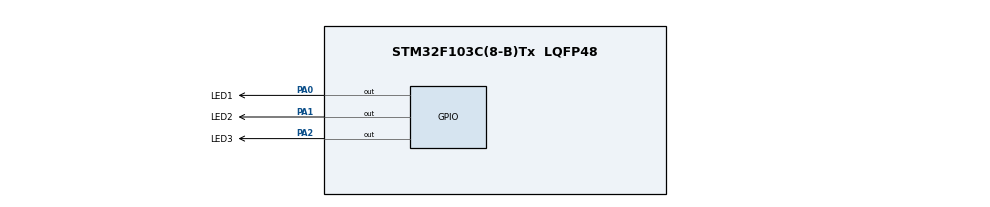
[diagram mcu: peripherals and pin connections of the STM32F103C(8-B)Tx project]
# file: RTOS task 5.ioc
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FREERTOS.Tasks01=defaultTask,0,128,StartDefaultTask,Default,NULL,Dynamic,NULL,NULL;GreenLEDTask,-3,128,green_led,Default,NULL,Dynamic,NULL,NULL;RedLEDTask,0,128,red_led,Default,NULL,Dynamic,NULL,NULL
Mcu.Family=STM32F1
Mcu.Name=STM32F103C(8-B)Tx
Mcu.Package=LQFP48
NVIC.PriorityGroup=NVIC_PRIORITYGROUP_4
PA0-WKUP.GPIO_Label=LED1
PA0-WKUP.Signal=GPIO_Output
PA1.GPIO_Label=LED2
PA1.Signal=GPIO_Output
PA13.Mode=Serial_Wire
PA13.Signal=SYS_JTMS-SWDIO
PA14.Mode=Serial_Wire
PA14.Signal=SYS_JTCK-SWCLK
PA2.GPIO_Label=LED3
PA2.Signal=GPIO_Output
ProjectManager.HeapSize=0x200
ProjectManager.StackSize=0x400
ProjectManager.TargetToolchain=STM32CubeIDE
RCC.APB1Freq_Value=8000000
RCC.APB2Freq_Value=8000000
VP_FREERTOS_VS_CMSIS_V1.Mode=CMSIS_V1
board=custom

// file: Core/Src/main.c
/* USER CODE BEGIN Header */
/**
  ******************************************************************************
  * @file           : main.c
  * @brief          : Main program body
  ******************************************************************************
  * @attention
  *
  * Copyright (c) 2024 STMicroelectronics.
  * All rights reserved.
  *
  * This software is licensed under terms that can be found in the LICENSE file
  * in the root directory of this software component.
  * If no LICENSE file comes with this software, it is provided AS-IS.
  *
  ******************************************************************************
  */
/* USER CODE END Header */
#include "main.h"
#include "cmsis_os.h"

/* USER CODE BEGIN PM */
volatile uint8_t startFlag = 1;
/* USER CODE END PM */

osThreadId defaultTaskHandle;
osThreadId GreenLEDTaskHandle;
osThreadId RedLEDTaskHandle;

void SystemClock_Config(void);
static void MX_GPIO_Init(void);
void StartDefaultTask(void const * argument);
void green_led(void const * argument);
void red_led(void const * argument);

int main(void)
{

  /* MCU Configuration--------------------------------------------------------*/

  /* Reset of all peripherals, Initializes the Flash interface and the Systick. */
  HAL_Init();

  /* Configure the system clock */
  SystemClock_Config();

  /* Initialize all configured peripherals */
  MX_GPIO_Init();

  /* Create the thread(s) */
  /* definition and creation of defaultTask */
  osThreadDef(defaultTask, StartDefaultTask, osPriorityNormal, 0, 128);
  defaultTaskHandle = osThreadCreate(osThread(defaultTask), NULL);

  /* definition and creation of GreenLEDTask */
  osThreadDef(GreenLEDTask, green_led, osPriorityIdle, 0, 128);
  GreenLEDTaskHandle = osThreadCreate(osThread(GreenLEDTask), NULL);

  /* definition and creation of RedLEDTask */
  osThreadDef(RedLEDTask, red_led, osPriorityNormal, 0, 128);
  RedLEDTaskHandle = osThreadCreate(osThread(RedLEDTask), NULL);

  /* Start scheduler */
  osKernelStart();

  /* We should never get here as control is now taken by the scheduler */

  /* Infinite loop */
  while (1)
  {

  }
}

void SystemClock_Config(void)
{
  RCC_OscInitTypeDef RCC_OscInitStruct = {0};
  RCC_ClkInitTypeDef RCC_ClkInitStruct = {0};

  /** Initializes the RCC Oscillators according to the specified parameters
  * in the RCC_OscInitTypeDef structure.
  */
  RCC_OscInitStruct.OscillatorType = RCC_OSCILLATORTYPE_HSI;
  RCC_OscInitStruct.HSIState = RCC_HSI_ON;
  RCC_OscInitStruct.HSICalibrationValue = RCC_HSICALIBRATION_DEFAULT;
  RCC_OscInitStruct.PLL.PLLState = RCC_PLL_NONE;
  if (HAL_RCC_OscConfig(&RCC_OscInitStruct) != HAL_OK)
  {
    Error_Handler();
  }

  /** Initializes the CPU, AHB and APB buses clocks
  */
  RCC_ClkInitStruct.ClockType = RCC_CLOCKTYPE_HCLK|RCC_CLOCKTYPE_SYSCLK
                              |RCC_CLOCKTYPE_PCLK1|RCC_CLOCKTYPE_PCLK2;
  RCC_ClkInitStruct.SYSCLKSource = RCC_SYSCLKSOURCE_HSI;
  RCC_ClkInitStruct.AHBCLKDivider = RCC_SYSCLK_DIV1;
  RCC_ClkInitStruct.APB1CLKDivider = RCC_HCLK_DIV1;
  RCC_ClkInitStruct.APB2CLKDivider = RCC_HCLK_DIV1;

  if (HAL_RCC_ClockConfig(&RCC_ClkInitStruct, FLASH_LATENCY_0) != HAL_OK)
  {
    Error_Handler();
  }
}

static void MX_GPIO_Init(void)
{
  GPIO_InitTypeDef GPIO_InitStruct = {0};

  /* GPIO Ports Clock Enable */
  __HAL_RCC_GPIOA_CLK_ENABLE();

  /*Configure GPIO pin Output Level */
  HAL_GPIO_WritePin(GPIOA, LED1_Pin|LED2_Pin|LED3_Pin, GPIO_PIN_RESET);

  /*Configure GPIO pins : LED1_Pin LED2_Pin LED3_Pin */
  GPIO_InitStruct.Pin = LED1_Pin|LED2_Pin|LED3_Pin;
  GPIO_InitStruct.Mode = GPIO_MODE_OUTPUT_PP;
  GPIO_InitStruct.Pull = GPIO_NOPULL;
  GPIO_InitStruct.Speed = GPIO_SPEED_FREQ_LOW;
  HAL_GPIO_Init(GPIOA, &GPIO_InitStruct);

}

void StartDefaultTask(void const * argument)
{
  for(;;)
  {
    osDelay(1);
  }
}

void green_led(void const * argument)
{
  /* USER CODE BEGIN green_led */
  /* Infinite loop */
	for(;;)
	  {
	    // Menyalakan LED hijau
	    HAL_GPIO_WritePin(GPIOA, GPIO_PIN_0, GPIO_PIN_SET);

	    // Akses data bersama
	    accessSharedData();

	    // Mematikan LED hijau
	    HAL_GPIO_WritePin(GPIOA, GPIO_PIN_0, GPIO_PIN_RESET);

	    // Menunda selama 0.5 detik
	    osDelay(500);
	  }
  /* USER CODE END green_led */
}

void red_led(void const * argument)
{
  /* USER CODE BEGIN red_led */
  /* Infinite loop */
	for(;;)
	  {
	    // Menyalakan LED merah
	    HAL_GPIO_WritePin(GPIOA, GPIO_PIN_1, GPIO_PIN_SET);

	    // Akses data bersama
	    accessSharedData();

	    // Mematikan LED merah
	    HAL_GPIO_WritePin(GPIOA, GPIO_PIN_1, GPIO_PIN_RESET);

	    // Menunda selama 0.1 detik
	    osDelay(100);
	  }
  /* USER CODE END red_led */
}
void accessSharedData(void)
{
  // Cek status startFlag
  if (startFlag == 1)
  {
    // Set flag ke 0
    startFlag = 0;
  }
  else
  {
    // Menyalakan LED biru untuk menunjukkan interferensi
    HAL_GPIO_WritePin(GPIOA, GPIO_PIN_2, GPIO_PIN_SET);
  }

  // Simulasi operasi baca/tulis selama 500 ms
  osDelay(500);

  // Mengatur kembali flag ke 1
  startFlag = 1;

  // Mematikan LED biru
  HAL_GPIO_WritePin(GPIOA, GPIO_PIN_2, GPIO_PIN_RESET);
}

void Error_Handler(void)
{
  __disable_irq();
  while (1)
  {
  }
}
